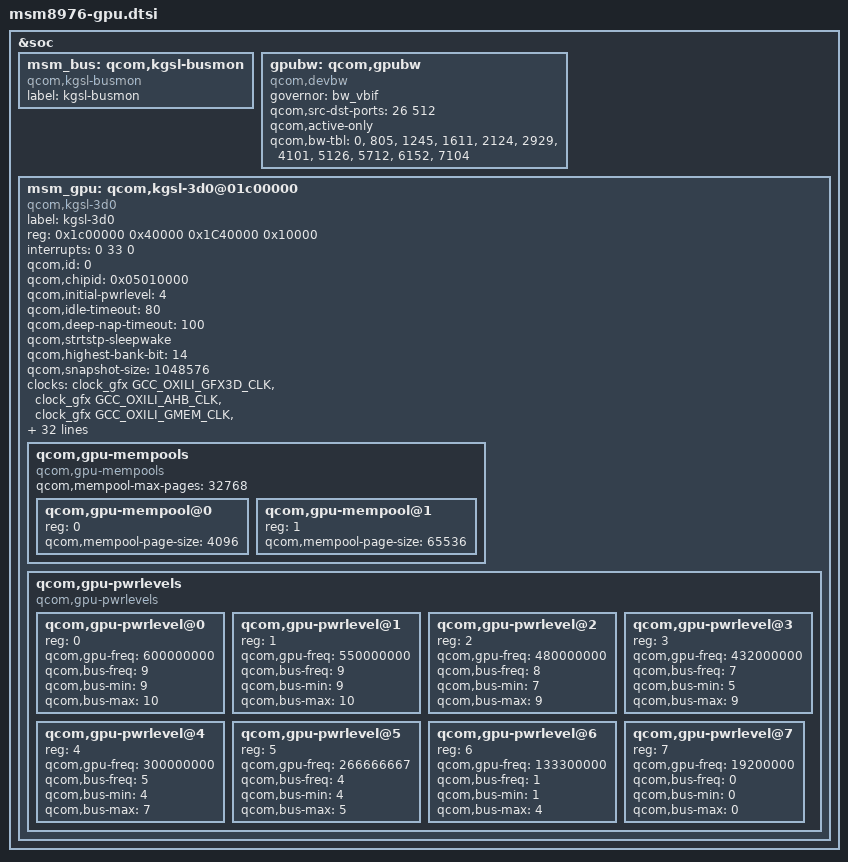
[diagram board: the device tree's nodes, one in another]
// SPDX-License-Identifier: GPL-2.0
// Copyright (c) 2015, The Linux Foundation. All rights reserved.
// Copyright (c) 2023, Benarji Anand <benarji385@gmail.com>

&soc {
	msm_bus: qcom,kgsl-busmon{
		label = "kgsl-busmon";
		compatible = "qcom,kgsl-busmon";
	};

	/* Bus governor */
	gpubw: qcom,gpubw {
		compatible = "qcom,devbw";
		governor = "bw_vbif";
		qcom,src-dst-ports = <26 512>;
		qcom,active-only;
		qcom,bw-tbl =
			< 0 >,    /* off                            */
			< 805  >, /* DDR: 105.6 MHz BIMC:  52.8 MHz */
			< 1245 >, /* DDR: 163.2 MHz BIMC:  81.6 MHz */
			< 1611 >, /* DDR: 211.2 MHz BIMC: 105.6 MHz */
			< 2124 >, /* DDR: 278.4 MHz BIMC: 139.2 MHz */
			< 2929 >, /* DDR: 384.0 MHz BIMC: 192.0 MHz */
			< 4101 >, /* DDR: 537.6 MHz BIMC: 268.8 MHz */
			< 5126 >, /* DDR: 672.0 MHz BIMC: 336.0 MHz */
			< 5712 >, /* DDR: 748.8 MHz BIMC: 374.4 MHz */
			< 6152 >, /* DDR: 806.4 MHz BIMC: 403.2 MHz */
			< 7104 >; /* DDR: 931.2 MHz BIMC: 465.6 MHz */
	};

	msm_gpu: qcom,kgsl-3d0@01c00000 {
		label = "kgsl-3d0";
		compatible = "qcom,kgsl-3d0", "qcom,kgsl-3d";
		reg = <0x1c00000 0x40000
			   0x1C40000 0x10000>;
		reg-names = "kgsl_3d0_reg_memory" , "kgsl_3d0_shader_memory";
		interrupts = <0 33 0>;
		interrupt-names = "kgsl_3d0_irq";
		qcom,id = <0>;

		qcom,chipid = <0x05010000>;

		qcom,initial-pwrlevel = <4>;

		qcom,idle-timeout = <80>; //msecs
		qcom,deep-nap-timeout = <100>; //msecs
		qcom,strtstp-sleepwake;

		qcom,highest-bank-bit = <14>;

		qcom,snapshot-size = <1048576>; //bytes

	clocks = <&clock_gfx GCC_OXILI_GFX3D_CLK>,
		 <&clock_gfx GCC_OXILI_AHB_CLK>,
		 <&clock_gfx GCC_OXILI_GMEM_CLK>,
		 <&clock_gfx GCC_BIMC_GFX_CLK>,
		 <&clock_gfx GCC_OXILI_TIMER_CLK>,
		 <&clock_gfx GCC_OXILI_AON_CLK>;

	clock-names =   "core_clk", "iface_clk", "mem_clk",
			"mem_iface_clk", "gtcu_iface_clk",
			"gtcu_clk", "rbbmtimer_clk", "aon_clk";

		/* Bus Scale Settings */
		qcom,gpubw-dev = <&gpubw>;
		qcom,bus-control;
		qcom,bus-width = <16>;
		qcom,msm-bus,name = "grp3d";
		qcom,msm-bus,num-cases = <11>;
		qcom,msm-bus,num-paths = <1>;
		qcom,msm-bus,vectors-KBps =
				<26 512 0 0>,	    /*  off          */
				<26 512 0 844800>,  /* 1. 105.6  MHz */
				<26 512 0 1305600>, /* 2. 163.2  MHz */
				<26 512 0 1689600>, /* 3. 211.2  MHz */
				<26 512 0 2227200>, /* 4. 278.4  MHz */
				<26 512 0 3072000>, /* 5. 384.0  MHz */
				<26 512 0 4300800>, /* 6. 537.6  MHz */
				<26 512 0 5376000>, /* 7. 672.0  MHz */
				<26 512 0 5990400>, /* 8. 748.8  MHz */
				<26 512 0 6451200>, /* 9. 806.4  MHz */
				<26 512 0 7449600>; /*10. 931.2  MHz */

		/* GDSC regulator names */
		regulator-names = "vddcx", "vdd";
		/* GDSC oxili regulators */
		vddcx-supply = <&gdsc_oxili_cx>;
		vdd-supply = <&gdsc_oxili_gx>;

		/* CPU latency parameter */
		qcom,pm-qos-active-latency = <213>;
		qcom,pm-qos-wakeup-latency = <213>;

		/* Quirks */
		qcom,gpu-quirk-two-pass-use-wfi;
		qcom,gpu-quirk-dp2clockgating-disable;
		qcom,gpu-quirk-lmloadkill-disable;

		/* Trace bus */
		coresight-id = <67>;
		coresight-name = "coresight-gfx";
		coresight-nr-inports = <0>;
		coresight-outports = <0>;
		coresight-child-list = <&funnel_in0>;
		coresight-child-ports = <4>;

		/* Enable context aware freq. scaling */
		qcom,enable-ca-jump;

		/* Context aware jump busy penalty in us */
		qcom,ca-busy-penalty = <12000>;

		/* Context aware jump target power level */
		qcom,ca-target-pwrlevel = <3>;

		/* Enable gpu cooling device */
		#cooling-cells = <2>;

		/* GPU Mempools */
		qcom,gpu-mempools {
			#address-cells= <1>;
			#size-cells = <0>;
			compatible = "qcom,gpu-mempools";

			qcom,mempool-max-pages = <32768>;

			/* 4K Page Pool configuration */
			qcom,gpu-mempool@0 {
				reg = <0>;
				qcom,mempool-page-size = <4096>;
			};
			/* 64K Page Pool configuration */
			qcom,gpu-mempool@1 {
				reg = <1>;
				qcom,mempool-page-size  = <65536>;
			};
		};

		/* Power levels */
		qcom,gpu-pwrlevels {
			#address-cells = <1>;
			#size-cells = <0>;

			compatible = "qcom,gpu-pwrlevels";

			/* TURBO */
			qcom,gpu-pwrlevel@0 {
				reg = <0>;
				qcom,gpu-freq = <600000000>;
				qcom,bus-freq = <9>;
				qcom,bus-min = <9>;
				qcom,bus-max = <10>;
			};

			/* NOM+ */
			qcom,gpu-pwrlevel@1 {
				reg = <1>;
				qcom,gpu-freq = <550000000>;
				qcom,bus-freq = <9>;
				qcom,bus-min = <9>;
				qcom,bus-max = <10>;
			};

			/* NOM */
			qcom,gpu-pwrlevel@2 {
				reg = <2>;
				qcom,gpu-freq = <480000000>;
				qcom,bus-freq = <8>;
				qcom,bus-min = <7>;
				qcom,bus-max = <9>;
			};

			/* SVS+ */
			qcom,gpu-pwrlevel@3 {
				reg = <3>;
				qcom,gpu-freq = <432000000>;
				qcom,bus-freq = <7>;
				qcom,bus-min = <5>;
				qcom,bus-max = <9>;
			};

			/* SVS */
			qcom,gpu-pwrlevel@4 {
				reg = <4>;
				qcom,gpu-freq = <300000000>;
				qcom,bus-freq = <5>;
				qcom,bus-min = <4>;
				qcom,bus-max = <7>;
			};

			/* Low SVS+ */
			qcom,gpu-pwrlevel@5 {
				reg = <5>;
				qcom,gpu-freq = <266666667>;
				qcom,bus-freq = <4>;
				qcom,bus-min = <4>;
				qcom,bus-max = <5>;
			};

		       /* Min SVS */
			qcom,gpu-pwrlevel@6 {
				reg = <6>;
				qcom,gpu-freq = <133300000>;
				qcom,bus-freq = <1>;
				qcom,bus-min = <1>;
				qcom,bus-max = <4>;
			};

			/* XO Clock */
			qcom,gpu-pwrlevel@7 {
				reg = <7>;
				qcom,gpu-freq = <19200000>;
				qcom,bus-freq = <0>;
				qcom,bus-min = <0>;
				qcom,bus-max = <0>;
			};
		};
	};
};
